AUTOSAR XML (schema 4-3-0)
package /ComponentTypes
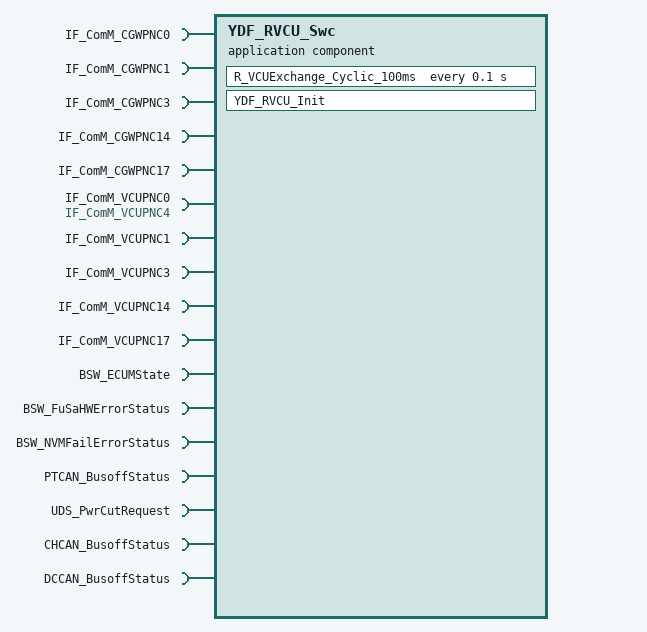
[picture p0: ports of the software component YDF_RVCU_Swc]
  application sw component type YDF_RVCU_Swc
    17 x require port:
      IF_ComM_CGWPNC0: nonqueued-receiver-com-spec{data-element=tec_ComM_CGWPNC0, init-value=0}, required-interface=IF_ComM_CGWPNC0
      IF_ComM_CGWPNC1: nonqueued-receiver-com-spec{data-element=tec_ComM_CGWPNC1, init-value=0}, required-interface=IF_ComM_CGWPNC1
      IF_ComM_CGWPNC3: nonqueued-receiver-com-spec{data-element=tec_ComM_CGWPNC3, init-value=0}, required-interface=IF_ComM_CGWPNC3
      IF_ComM_CGWPNC14: nonqueued-receiver-com-spec{data-element=tec_ComM_CGWPNC14, init-value=0}, required-interface=IF_ComM_CGWPNC14
      IF_ComM_CGWPNC17: nonqueued-receiver-com-spec{data-element=tec_ComM_CGWPNC17, init-value=0}, required-interface=IF_ComM_CGWPNC17
      IF_ComM_VCUPNC0: nonqueued-receiver-com-spec{data-element=tec_ComM_VCUPNC4, init-value=0}, required-interface=IF_ComM_VCUPNC4
      IF_ComM_VCUPNC1: nonqueued-receiver-com-spec{data-element=tec_ComM_VCUPNC1, init-value=0}, required-interface=IF_ComM_VCUPNC1
      IF_ComM_VCUPNC3: nonqueued-receiver-com-spec{data-element=tec_ComM_VCUPNC3, init-value=0}, required-interface=IF_ComM_VCUPNC3
      IF_ComM_VCUPNC14: nonqueued-receiver-com-spec{data-element=tec_ComM_VCUPNC14, init-value=0}, required-interface=IF_ComM_VCUPNC14
      IF_ComM_VCUPNC17: nonqueued-receiver-com-spec{data-element=tec_ComM_VCUPNC17, init-value=0}, required-interface=IF_ComM_VCUPNC17
      BSW_ECUMState: nonqueued-receiver-com-spec{data-element=BSWState, init-value=0}, required-interface=BSW_ECUMState
      BSW_FuSaHWErrorStatus: nonqueued-receiver-com-spec{data-element=HWErrorStatus, init-value=0}, required-interface=BSW_FuSaHWErrorStatus
      BSW_NVMFailErrorStatus: nonqueued-receiver-com-spec{data-element=NVMFailErrorStatus, init-value=0}, required-interface=BSW_NVMFailErrorStatus
      PTCAN_BusoffStatus: nonqueued-receiver-com-spec{data-element=BusoffStatus, init-value=0}, required-interface=PTCAN_BusoffStatus
      UDS_PwrCutRequest: nonqueued-receiver-com-spec{data-element=PwrCutRequest, init-value=0}, required-interface=UDS_PwrCutRequest
      CHCAN_BusoffStatus: nonqueued-receiver-com-spec{data-element=BusoffStatus, init-value=0}, required-interface=CHCAN_BusoffStatus
      DCCAN_BusoffStatus: nonqueued-receiver-com-spec{data-element=BusoffStatus, init-value=0}, required-interface=DCCAN_BusoffStatus
    behavior YDF_RVCU_Swc_InternalBehavior
      init event YDF_RVCU_Swc_InitEvent: start-on-event=YDF_RVCU_Init
      timing event TMT_R_VCUExchange_Cyclic_100ms: start-on-event=R_VCUExchange_Cyclic_100ms, period=0.1
      runnable YDF_RVCU_Init
      runnable R_VCUExchange_Cyclic_100ms
        data-receive-point-by-arguments:
          17 x access:
            REC_IF_ComM_CGWPNC0_CgwPNC0: accessed-variable=IF_ComM_CGWPNC0.tec_ComM_CGWPNC0
            REC_IF_ComM_CGWPNC1_CgwPNC1: accessed-variable=IF_ComM_CGWPNC1.tec_ComM_CGWPNC1
            REC_IF_ComM_CGWPNC14_CgwPNC14: accessed-variable=IF_ComM_CGWPNC14.tec_ComM_CGWPNC14
            REC_IF_ComM_CGWPNC17_CgwPNC17: accessed-variable=IF_ComM_CGWPNC17.tec_ComM_CGWPNC17
            REC_IF_ComM_CGWPNC3_CgwPNC3: accessed-variable=IF_ComM_CGWPNC3.tec_ComM_CGWPNC3
            REC_IF_ComM_VCUPNC0_VcuPNC0: accessed-variable=IF_ComM_VCUPNC0.tec_ComM_VCUPNC4
            REC_IF_ComM_VCUPNC1_VcuPNC1: accessed-variable=IF_ComM_VCUPNC1.tec_ComM_VCUPNC1
            REC_IF_ComM_VCUPNC14_VcuPNC14: accessed-variable=IF_ComM_VCUPNC14.tec_ComM_VCUPNC14
            REC_IF_ComM_VCUPNC17_VcuPNC17: accessed-variable=IF_ComM_VCUPNC17.tec_ComM_VCUPNC17
            REC_IF_ComM_VCUPNC3_VcuPNC3: accessed-variable=IF_ComM_VCUPNC3.tec_ComM_VCUPNC3
            REC_BSW_ECUMState_BSWState: accessed-variable=BSW_ECUMState.BSWState
            REC_BSW_FuSaHWErrorStatus_HWErrorStatus: accessed-variable=BSW_FuSaHWErrorStatus.HWErrorStatus
            REC_BSW_NVMFailErrorStatus_NVMFailErrorStatus: accessed-variable=BSW_NVMFailErrorStatus.NVMFailErrorStatus
            REC_CHCAN_BusoffStatus_BusoffStatus: accessed-variable=CHCAN_BusoffStatus.BusoffStatus
            REC_DCCAN_BusoffStatus_BusoffStatus: accessed-variable=DCCAN_BusoffStatus.BusoffStatus
            REC_PTCAN_BusoffStatus_BusoffStatus: accessed-variable=PTCAN_BusoffStatus.BusoffStatus
            REC_UDS_PwrCutRequest_PwrCutRequest: accessed-variable=UDS_PwrCutRequest.PwrCutRequest
  swc implementation YDF_RVCU_Swc_Implementation: behavior=YDF_RVCU_Swc_InternalBehavior
